# PIC32MZ0512EFE144 register map
Vendor: Microchip
Registers are 32-bit, read-write, reset 0x0 unless marked. A register's access mark holds for its fields unless they carry their own. Addresses are absolute, and some are shared; only a register's first bit layout is shown; [hi:lo] are bit positions; {n}, {i} and the like mark numbered series; 'fields as' and 'values as' point back to an identical list.

## PORTJ
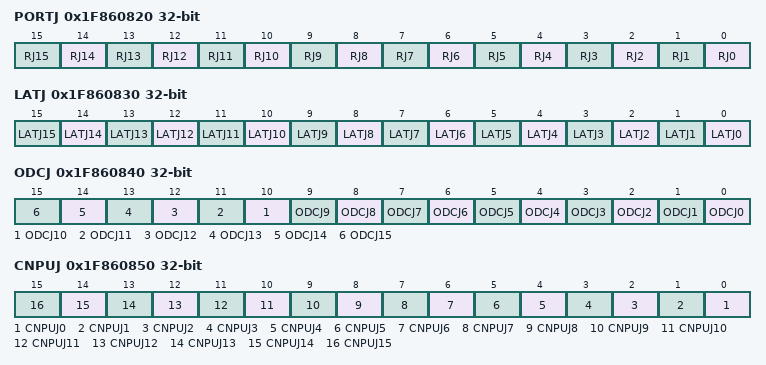
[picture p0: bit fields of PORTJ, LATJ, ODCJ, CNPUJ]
0x1F860820 PORTJ reset not defined — (power-on value ----------------xxxxxxxxxxxxxxxx)
  [n] RJ{n} (n=0..15)
0x1F860830 LATJ reset not defined — (power-on value ----------------xxxxxxxxxxxxxxxx)
  [n] LATJ{n} (n=0..15)
0x1F860840 ODCJ
  [n] ODCJ{n} (n=0..15)
0x1F860850 CNPUJ
  [n] CNPUJ{n} (n=0..15)
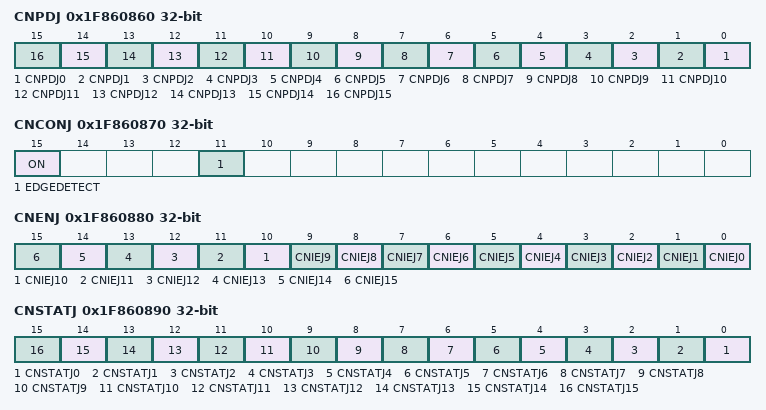
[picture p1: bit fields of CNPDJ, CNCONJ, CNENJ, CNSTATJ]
0x1F860860 CNPDJ
  [n] CNPDJ{n} (n=0..15)
0x1F860870 CNCONJ
  [15] ON, [11] EDGEDETECT
0x1F860880 CNENJ
  [n] CNIEJ{n} (n=0..15)
0x1F860890 CNSTATJ
  [n] CNSTATJ{n} (n=0..15)
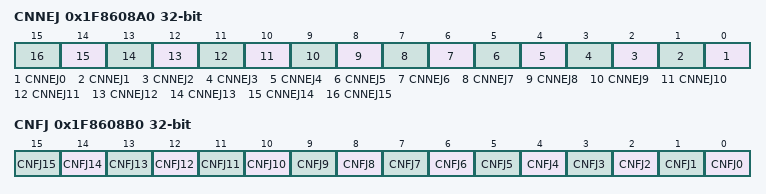
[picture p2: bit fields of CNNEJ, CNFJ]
0x1F8608A0 CNNEJ
  [n] CNNEJ{n} (n=0..15)
0x1F8608B0 CNFJ
  [n] CNFJ{n} (n=0..15)

## PORTK
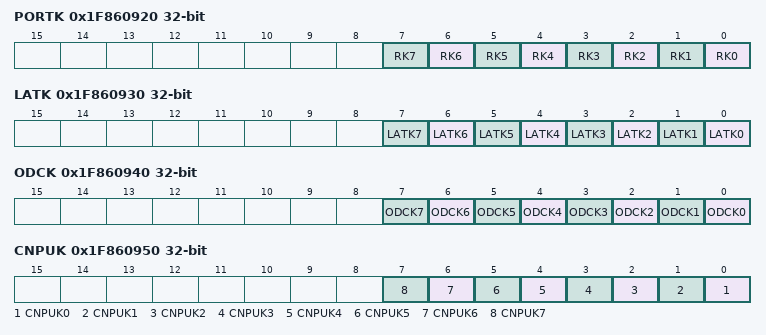
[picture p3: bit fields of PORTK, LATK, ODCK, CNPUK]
0x1F860920 PORTK reset not defined — (power-on value ------------------------xxxxxxxx)
  [n] RK{n} (n=0..7)
0x1F860930 LATK reset not defined — (power-on value ------------------------xxxxxxxx)
  [n] LATK{n} (n=0..7)
0x1F860940 ODCK
  [n] ODCK{n} (n=0..7)
0x1F860950 CNPUK
  [n] CNPUK{n} (n=0..7)
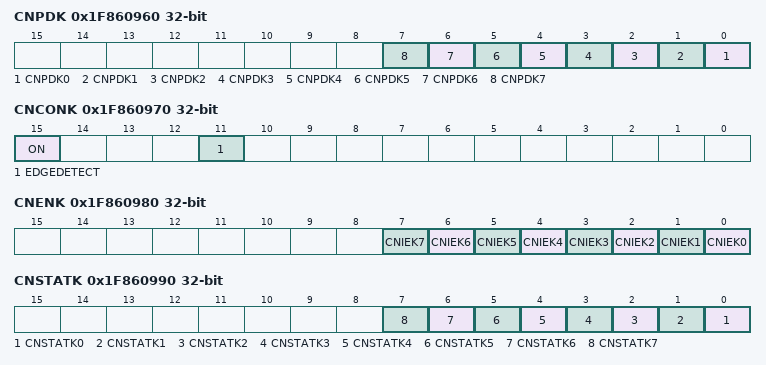
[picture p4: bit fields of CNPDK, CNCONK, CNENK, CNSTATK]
0x1F860960 CNPDK
  [n] CNPDK{n} (n=0..7)
0x1F860970 CNCONK
  [15] ON, [11] EDGEDETECT
0x1F860980 CNENK
  [n] CNIEK{n} (n=0..7)
0x1F860990 CNSTATK
  [n] CNSTATK{n} (n=0..7)
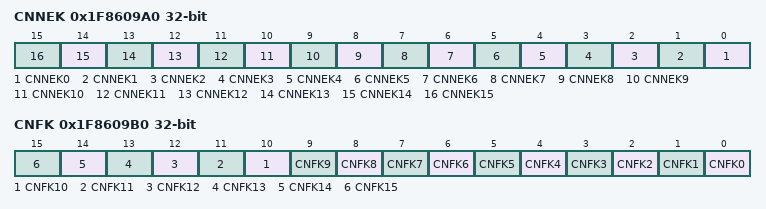
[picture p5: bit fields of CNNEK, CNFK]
0x1F8609A0 CNNEK
  [n] CNNEK{n} (n=0..15)
0x1F8609B0 CNFK
  [n] CNFK{n} (n=0..15)

## usb_clk_rst
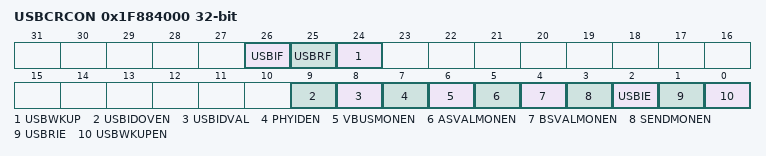
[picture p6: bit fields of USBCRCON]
0x1F884000 USBCRCON
  [26] USBIF ro, [25] USBRF, [24] USBWKUP, [9] USBIDOVEN, [8] USBIDVAL, [7] PHYIDEN, [6] VBUSMONEN, [5] ASVALMONEN, [4] BSVALMONEN, [3] SENDMONEN, [2] USBIE, [1] USBRIE, [0] USBWKUPEN

## PCACHE
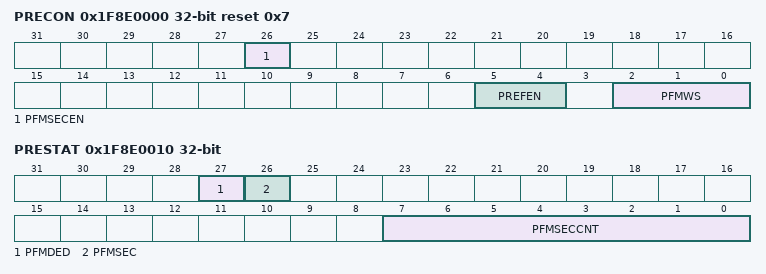
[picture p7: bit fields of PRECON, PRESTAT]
0x1F8E0000 PRECON reset 0x7
  [26] PFMSECEN, [5:4] PREFEN, [2:0] PFMWS
0x1F8E0010 PRESTAT
  [27] PFMDED, [26] PFMSEC, [7:0] PFMSECCNT

## EBI
{0x1F8E1014+4i} EBICS{i} (i=0..3)
  [31:16] CSADDR
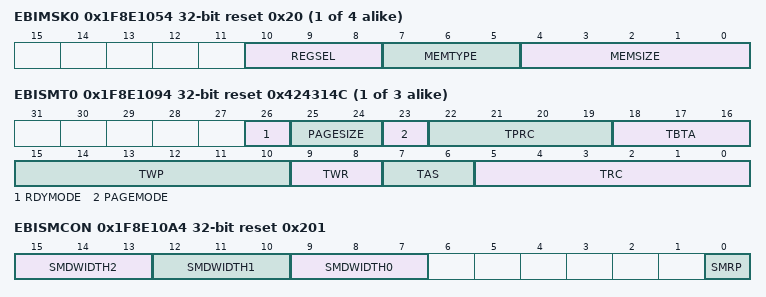
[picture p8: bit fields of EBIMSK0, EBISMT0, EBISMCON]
{0x1F8E1054+4i} EBIMSK{i} reset 0x20 (i=0..3)
  [10:8] REGSEL, [7:5] MEMTYPE, [4:0] MEMSIZE
{0x1F8E1094+4i} EBISMT{i} reset 0x424314C (i=0..2)
  [26] RDYMODE, [25:24] PAGESIZE, [23] PAGEMODE, [22:19] TPRC, [18:16] TBTA, [15:10] TWP, [9:8] TWR, [7:6] TAS, [5:0] TRC
0x1F8E10A0 EBIFTRPD reset 0x201
  [31:0] TRPD
0x1F8E10A4 EBISMCON reset 0x201
  [15:13] SMDWIDTH2, [12:10] SMDWIDTH1, [9:7] SMDWIDTH0, [0] SMRP

## DOS_EIP_00124_usb_hs_otgcore
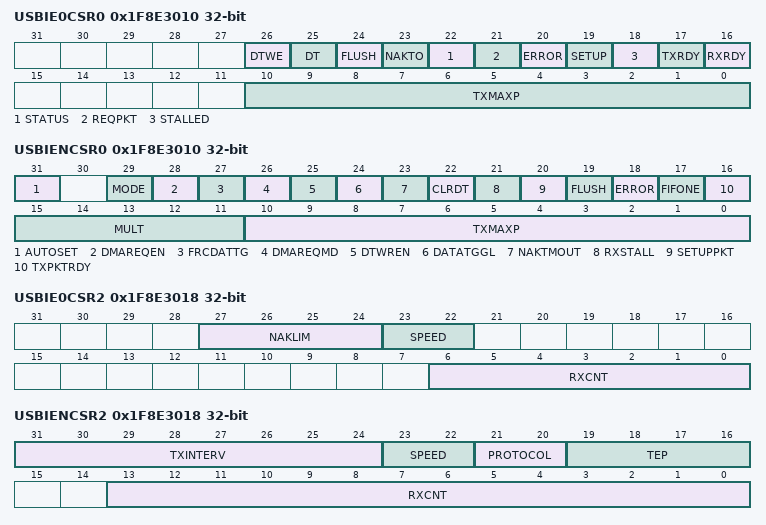
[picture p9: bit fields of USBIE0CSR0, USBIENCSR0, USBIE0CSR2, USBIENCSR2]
0x1F8E3010 USBIE0CSR0
  [26] DTWE, [25] DT, [24] FLUSH, [23] NAKTO, [22] STATUS, [21] REQPKT, [20] ERROR, [19] SETUP, [18] STALLED, [17] TXRDY, [16] RXRDY, [10:0] TXMAXP
0x1F8E3010 USBIENCSR0
  [31] AUTOSET, [29] MODE, [28] DMAREQEN, [27] FRCDATTG, [26] DMAREQMD, [25] DTWREN, [24] DATATGGL, [23] NAKTMOUT, [22] CLRDT, [21] RXSTALL, [20] SETUPPKT, [19] FLUSH, [18] ERROR, [17] FIFONE, [16] TXPKTRDY, [15:11] MULT, [10:0] TXMAXP
0x1F8E3018 USBIE0CSR2
  [27:24] NAKLIM, [23:22] SPEED, [6:0] RXCNT ro
0x1F8E3018 USBIENCSR2
  [31:24] TXINTERV, [23:22] SPEED, [21:20] PROTOCOL, [19:16] TEP, [13:0] RXCNT ro
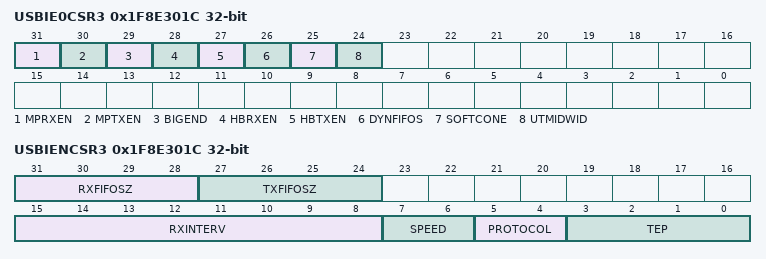
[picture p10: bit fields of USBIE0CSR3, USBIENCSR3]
0x1F8E301C USBIE0CSR3 ro reset not defined — (power-on value xx0xxx10------------------------)
  [31] MPRXEN, [30] MPTXEN, [29] BIGEND, [28] HBRXEN, [27] HBTXEN, [26] DYNFIFOS, [25] SOFTCONE, [24] UTMIDWID
0x1F8E301C USBIENCSR3 reset not defined — (power-on value xxxxxxxx--------0000000000000000)
  [31:28] RXFIFOSZ ro, [27:24] TXFIFOSZ ro, [15:8] RXINTERV, [7:6] SPEED, [5:4] PROTOCOL, [3:0] TEP

## RNG
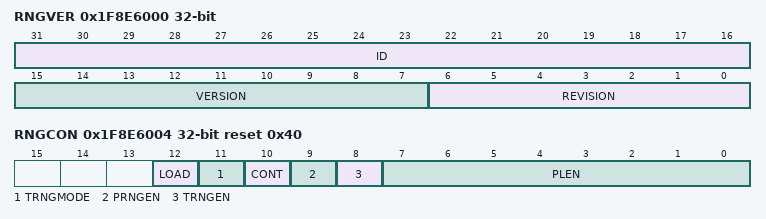
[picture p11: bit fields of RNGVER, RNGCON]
0x1F8E6000 RNGVER ro
  [31:16] ID, [15:7] VERSION, [6:0] REVISION
0x1F8E6004 RNGCON reset 0x40
  [12] LOAD, [11] TRNGMODE, [10] CONT, [9] PRNGEN, [8] TRNGEN, [7:0] PLEN
0x1F8E6008 RNGPOLY1 reset 0xFFFF0000
  [31:0] POLY
0x1F8E600C RNGPOLY2 reset 0xFFFF0000
  [31:0] POLY
0x1F8E6010 RNGNUMGEN1 reset 0xFFFFFFFF
  [31:0] RNG
0x1F8E6014 RNGNUMGEN2 reset 0xFFFFFFFF
  [31:0] RNG
0x1F8E6018 RNGSEED1 ro
  [31:0] SEED
0x1F8E601C RNGSEED2 ro
  [31:0] SEED
0x1F8E6020 RNGCNT
  [6:0] RCNT

## SB
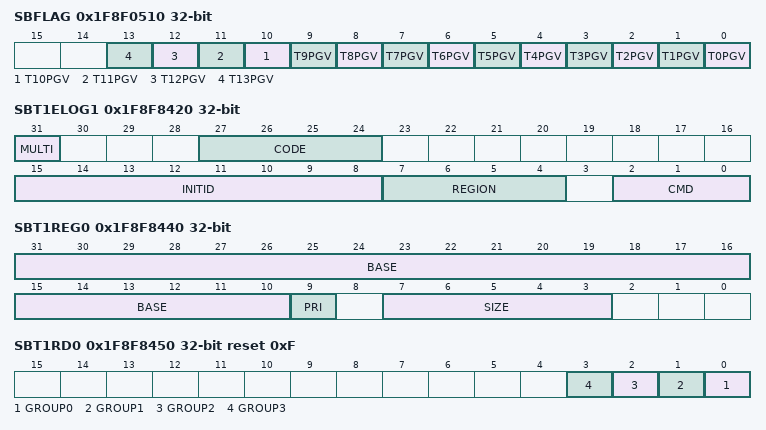
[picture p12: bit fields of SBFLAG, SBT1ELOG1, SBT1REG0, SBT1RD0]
0x1F8F0510 SBFLAG ro
  [n] T{n}PGV (n=0..13)
0x1F8F8420 SBT1ELOG1
  [31] MULTI, [27:24] CODE, [15:8] INITID ro, [7:4] REGION ro, [2:0] CMD ro
0x1F8F8424 SBT1ELOG2 ro
  [1:0] GROUP
0x1F8F8428 SBT1ECON
  [24] ERRP
0x1F8F8430 SBT1ECLRS ro
  [0] CLEAR
0x1F8F8438 SBT1ECLRM ro
  [0] CLEAR
0x1F8F8440 SBT1REG0 reset not defined — (power-on value 0000000000000000000000x-00000---)
  [31:10] BASE, [9] PRI ro, [7:3] SIZE
0x1F8F8450 SBT1RD0 reset 0xF
  [n] GROUP{n} (n=0..3)
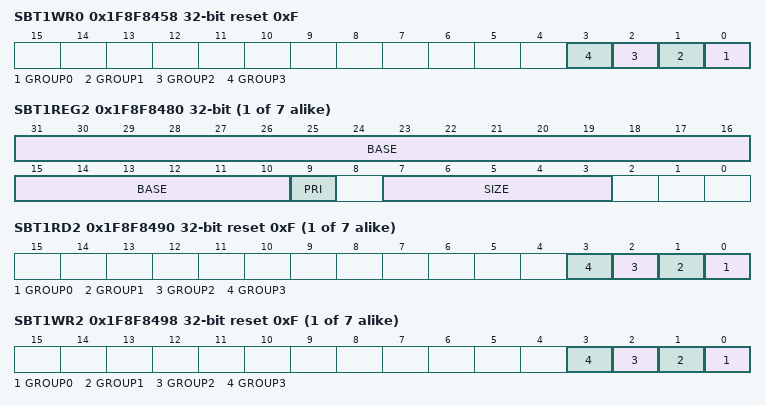
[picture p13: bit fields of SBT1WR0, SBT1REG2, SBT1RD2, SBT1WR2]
0x1F8F8458 SBT1WR0 reset 0xF
  [n] GROUP{n} (n=0..3)
{0x1F8F8440+0x20*i} SBT1REG{i} reset not defined (i=2..8) — (power-on value 0000000000000000000000x-00000---)
  [31:10] BASE, [9] PRI ro, [7:3] SIZE
{0x1F8F8450+0x20*i} SBT1RD{i} reset 0xF (i=2..8)
  [n] GROUP{n} (n=0..3)
{0x1F8F8458+0x20*i} SBT1WR{i} reset 0xF (i=2..8)
  [n] GROUP{n} (n=0..3)

## DOS_EIP_00136_ssx
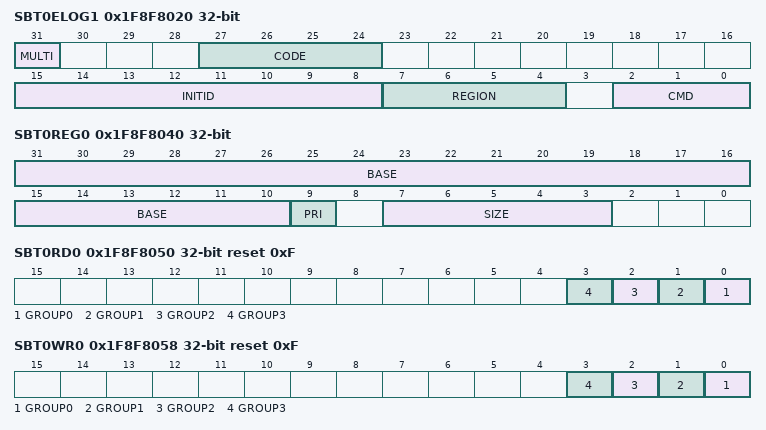
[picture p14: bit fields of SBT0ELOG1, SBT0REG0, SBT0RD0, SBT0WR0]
0x1F8F8020 SBT0ELOG1
  [31] MULTI, [27:24] CODE, [15:8] INITID ro, [7:4] REGION ro, [2:0] CMD ro
0x1F8F8024 SBT0ELOG2 ro
  [1:0] GROUP
0x1F8F8028 SBT0ECON
  [24] ERRP
0x1F8F8030 SBT0ECLRS ro
  [0] CLEAR
0x1F8F8038 SBT0ECLRM ro
  [0] CLEAR
0x1F8F8040 SBT0REG0 reset not defined — (power-on value 0000000000000000000000x-00000---)
  [31:10] BASE, [9] PRI ro, [7:3] SIZE
0x1F8F8050 SBT0RD0 reset 0xF
  [n] GROUP{n} (n=0..3)
0x1F8F8058 SBT0WR0 reset 0xF
  [n] GROUP{n} (n=0..3)
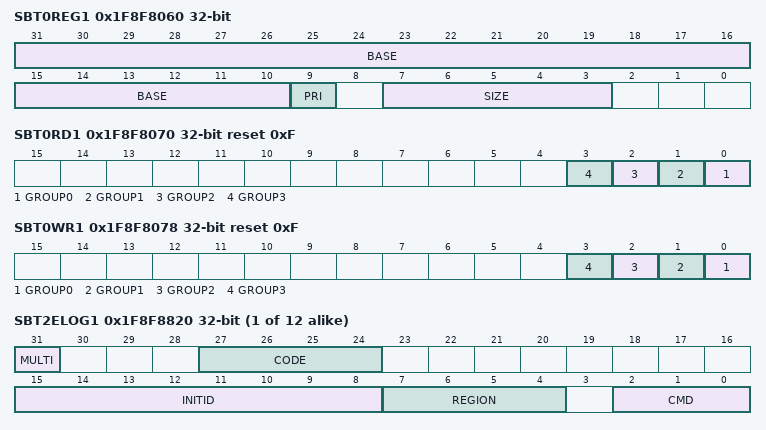
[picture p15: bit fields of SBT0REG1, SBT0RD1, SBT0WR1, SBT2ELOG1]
0x1F8F8060 SBT0REG1 reset not defined — (power-on value 0000000000000000000000x-00000---)
  [31:10] BASE, [9] PRI ro, [7:3] SIZE
0x1F8F8070 SBT0RD1 reset 0xF
  [n] GROUP{n} (n=0..3)
0x1F8F8078 SBT0WR1 reset 0xF
  [n] GROUP{n} (n=0..3)
{0x1F8F8020+0x400*i} SBT{i}ELOG1 (i=2..13)
  fields as SBT0ELOG1
{0x1F8F8024+0x400*i} SBT{i}ELOG2 ro (i=2..13)
  [1:0] GROUP
{0x1F8F8028+0x400*i} SBT{i}ECON (i=2..13)
  [24] ERRP
{0x1F8F8030+0x400*i} SBT{i}ECLRS ro (i=2..13)
  [0] CLEAR
{0x1F8F8038+0x400*i} SBT{i}ECLRM ro (i=2..13)
  [0] CLEAR
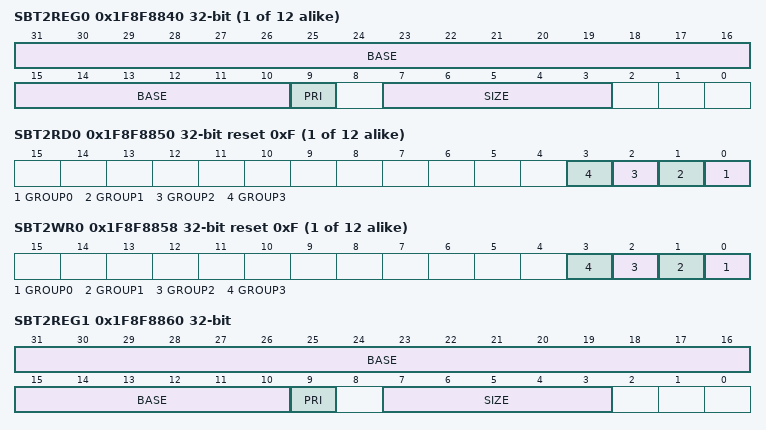
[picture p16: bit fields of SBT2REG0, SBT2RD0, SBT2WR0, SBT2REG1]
{0x1F8F8040+0x400*i} SBT{i}REG0 reset not defined (i=2..13) — (power-on value 0000000000000000000000x-00000---)
  [31:10] BASE, [9] PRI ro, [7:3] SIZE
{0x1F8F8050+0x400*i} SBT{i}RD0 reset 0xF (i=2..13)
  [n] GROUP{n} (n=0..3)
{0x1F8F8058+0x400*i} SBT{i}WR0 reset 0xF (i=2..13)
  [n] GROUP{n} (n=0..3)
0x1F8F8860 SBT2REG1 reset not defined — (power-on value 0000000000000000000000x-00000---)
  [31:10] BASE, [9] PRI ro, [7:3] SIZE
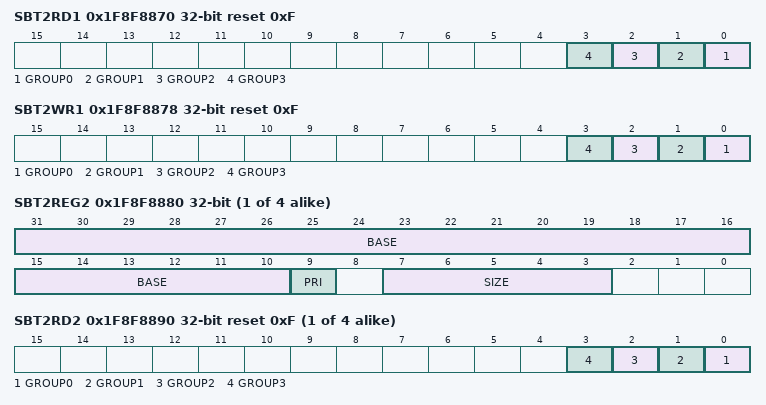
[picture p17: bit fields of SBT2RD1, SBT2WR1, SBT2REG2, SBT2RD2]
0x1F8F8870 SBT2RD1 reset 0xF
  [n] GROUP{n} (n=0..3)
0x1F8F8878 SBT2WR1 reset 0xF
  [n] GROUP{n} (n=0..3)
{0x1F8F8080+0x400*i} SBT{i}REG2 reset not defined (i=2..5) — (power-on value 0000000000000000000000x-00000---)
  [31:10] BASE, [9] PRI ro, [7:3] SIZE
{0x1F8F8090+0x400*i} SBT{i}RD2 reset 0xF (i=2..5)
  [n] GROUP{n} (n=0..3)
{0x1F8F8098+0x400*i} SBT{i}WR2 reset 0xF (i=2..5)
  [n] GROUP{n} (n=0..3)
0x1F8F8C60 SBT3REG1 reset not defined — (power-on value 0000000000000000000000x-00000---)
  [31:10] BASE, [9] PRI ro, [7:3] SIZE
0x1F8F8C70 SBT3RD1 reset 0xF
  [n] GROUP{n} (n=0..3)
0x1F8F8C78 SBT3WR1 reset 0xF
  [n] GROUP{n} (n=0..3)
{0x1F8F8060+0x400*i} SBT{i}REG1 reset not defined (i=5..9) — (power-on value 0000000000000000000000x-00000---)
  [31:10] BASE, [9] PRI ro, [7:3] SIZE
{0x1F8F8070+0x400*i} SBT{i}RD1 reset 0xF (i=5..9)
  [n] GROUP{n} (n=0..3)
{0x1F8F8078+0x400*i} SBT{i}WR1 reset 0xF (i=5..9)
  [n] GROUP{n} (n=0..3)
0x1F8FAC60 SBT11REG1 reset not defined — (power-on value 0000000000000000000000x-00000---)
  [31:10] BASE, [9] PRI ro, [7:3] SIZE
0x1F8FAC70 SBT11RD1 reset 0xF
  [n] GROUP{n} (n=0..3)
0x1F8FAC78 SBT11WR1 reset 0xF
  [n] GROUP{n} (n=0..3)
